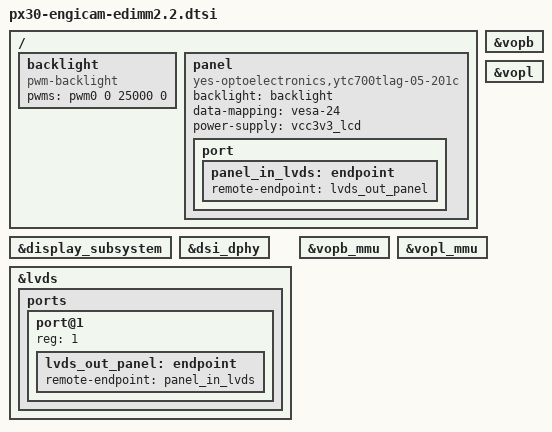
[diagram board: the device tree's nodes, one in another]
// SPDX-License-Identifier: (GPL-2.0+ OR MIT)
/*
 * Copyright (c) 2020 Engicam srl
 * Copyright (c) 2020 Amarula Solutions(India)
 */

#include "px30-engicam-common.dtsi"

/ {
	backlight: backlight {
		compatible = "pwm-backlight";
		pwms = <&pwm0 0 25000 0>;
	};

	panel {
		compatible = "yes-optoelectronics,ytc700tlag-05-201c";
		backlight = <&backlight>;
		data-mapping = "vesa-24";
		power-supply = <&vcc3v3_lcd>;

		port {
			panel_in_lvds: endpoint {
				remote-endpoint = <&lvds_out_panel>;
			};
		};
	};
};

&display_subsystem {
	status = "okay";
};

&dsi_dphy {
	status = "okay";
};

/* LVDS_B(secondary) */
&lvds {
	status = "okay";

	ports {
		port@1 {
			reg = <1>;

			lvds_out_panel: endpoint {
				remote-endpoint = <&panel_in_lvds>;
			};
		};
	};
};

&vopb {
	status = "okay";
};

&vopb_mmu {
	status = "okay";
};

&vopl {
	status = "okay";
};

&vopl_mmu {
	status = "okay";
};
